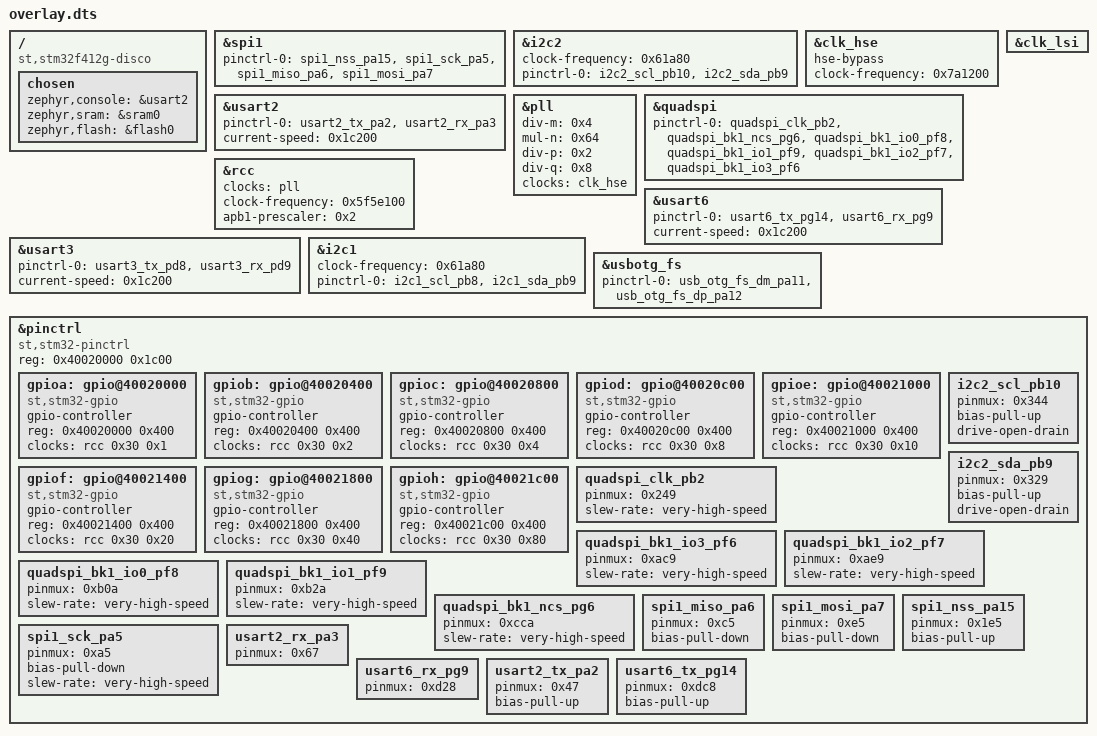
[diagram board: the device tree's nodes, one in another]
/ {
	compatible = "st,stm32f412g-disco";
	chosen {
		zephyr,console = &usart2;
		zephyr,sram = &sram0;
		zephyr,flash = &flash0;
	};
};
&spi1{
	status = "okay";
	pinctrl-0 = < &spi1_nss_pa15 &spi1_sck_pa5 &spi1_miso_pa6 &spi1_mosi_pa7 >;
	pinctrl-names = "default";
};
&i2c2{
	clock-frequency = < 0x61a80 >;
	status = "okay";
	pinctrl-0 = < &i2c2_scl_pb10 &i2c2_sda_pb9 >;
	pinctrl-names = "default";
};
&clk_hse{
	status = "okay";
	hse-bypass;
	clock-frequency = < 0x7a1200 >;
};
&clk_lsi{
	status = "okay";
};
&usart2{
	status = "okay";
	pinctrl-0 = < &usart2_tx_pa2 &usart2_rx_pa3 >;
	pinctrl-names = "default";
	current-speed = < 0x1c200 >;
};
&pll{
	status = "okay";
	div-m = < 0x4 >;
	mul-n = < 0x64 >;
	div-p = < 0x2 >;
	div-q = < 0x8 >;
	clocks = < &clk_hse >;
};
&quadspi{
	status = "okay";
	pinctrl-0 = < &quadspi_clk_pb2 &quadspi_bk1_ncs_pg6 &quadspi_bk1_io0_pf8 &quadspi_bk1_io1_pf9 &quadspi_bk1_io2_pf7 &quadspi_bk1_io3_pf6 >;
	pinctrl-names = "default";
};
&rcc{
	clocks = < &pll >;
	clock-frequency = < 0x5f5e100 >;
	apb1-prescaler = < 0x2 >;
};
&usart6{
	status = "okay";
	pinctrl-0 = < &usart6_tx_pg14 &usart6_rx_pg9 >;
	pinctrl-names = "default";
	current-speed = < 0x1c200 >;
};
&usart3{
	status = "okay";
	pinctrl-0 = < &usart3_tx_pd8 &usart3_rx_pd9 >;
	pinctrl-names = "default";
	current-speed = < 0x1c200 >;
};
&i2c1{
	clock-frequency = < 0x61a80 >;
	status = "okay";
	pinctrl-0 = < &i2c1_scl_pb8 &i2c1_sda_pb9 >;
	pinctrl-names = "default";
};
&usbotg_fs{
	status = "okay";
	pinctrl-0 = < &usb_otg_fs_dm_pa11 &usb_otg_fs_dp_pa12 >;
	pinctrl-names = "default";
};
&pinctrl{
	compatible = "st,stm32-pinctrl";
	#address-cells = < 0x1 >;
	#size-cells = < 0x1 >;
	reg = < 0x40020000 0x1c00 >;
	gpioa: gpio@40020000 {
		compatible = "st,stm32-gpio";
		gpio-controller;
		#gpio-cells = < 0x2 >;
		reg = < 0x40020000 0x400 >;
		clocks = < &rcc 0x30 0x1 >;
	};
	gpiob: gpio@40020400 {
		compatible = "st,stm32-gpio";
		gpio-controller;
		#gpio-cells = < 0x2 >;
		reg = < 0x40020400 0x400 >;
		clocks = < &rcc 0x30 0x2 >;
	};
	gpioc: gpio@40020800 {
		compatible = "st,stm32-gpio";
		gpio-controller;
		#gpio-cells = < 0x2 >;
		reg = < 0x40020800 0x400 >;
		clocks = < &rcc 0x30 0x4 >;
	};
	gpiod: gpio@40020c00 {
		compatible = "st,stm32-gpio";
		gpio-controller;
		#gpio-cells = < 0x2 >;
		reg = < 0x40020c00 0x400 >;
		clocks = < &rcc 0x30 0x8 >;
	};
	gpioe: gpio@40021000 {
		compatible = "st,stm32-gpio";
		gpio-controller;
		#gpio-cells = < 0x2 >;
		reg = < 0x40021000 0x400 >;
		clocks = < &rcc 0x30 0x10 >;
	};
	gpiof: gpio@40021400 {
		compatible = "st,stm32-gpio";
		gpio-controller;
		#gpio-cells = < 0x2 >;
		reg = < 0x40021400 0x400 >;
		clocks = < &rcc 0x30 0x20 >;
	};
	gpiog: gpio@40021800 {
		compatible = "st,stm32-gpio";
		gpio-controller;
		#gpio-cells = < 0x2 >;
		reg = < 0x40021800 0x400 >;
		clocks = < &rcc 0x30 0x40 >;
	};
	gpioh: gpio@40021c00 {
		compatible = "st,stm32-gpio";
		gpio-controller;
		#gpio-cells = < 0x2 >;
		reg = < 0x40021c00 0x400 >;
		clocks = < &rcc 0x30 0x80 >;
	};
	i2c2_scl_pb10: i2c2_scl_pb10 {
		pinmux = < 0x344 >;
		bias-pull-up;
		drive-open-drain;
	};
	i2c2_sda_pb9: i2c2_sda_pb9 {
		pinmux = < 0x329 >;
		bias-pull-up;
		drive-open-drain;
	};
	quadspi_clk_pb2: quadspi_clk_pb2 {
		pinmux = < 0x249 >;
		slew-rate = "very-high-speed";
	};
	quadspi_bk1_io3_pf6: quadspi_bk1_io3_pf6 {
		pinmux = < 0xac9 >;
		slew-rate = "very-high-speed";
	};
	quadspi_bk1_io2_pf7: quadspi_bk1_io2_pf7 {
		pinmux = < 0xae9 >;
		slew-rate = "very-high-speed";
	};
	quadspi_bk1_io0_pf8: quadspi_bk1_io0_pf8 {
		pinmux = < 0xb0a >;
		slew-rate = "very-high-speed";
	};
	quadspi_bk1_io1_pf9: quadspi_bk1_io1_pf9 {
		pinmux = < 0xb2a >;
		slew-rate = "very-high-speed";
	};
	quadspi_bk1_ncs_pg6: quadspi_bk1_ncs_pg6 {
		pinmux = < 0xcca >;
		slew-rate = "very-high-speed";
	};
	spi1_miso_pa6: spi1_miso_pa6 {
		pinmux = < 0xc5 >;
		bias-pull-down;
	};
	spi1_mosi_pa7: spi1_mosi_pa7 {
		pinmux = < 0xe5 >;
		bias-pull-down;
	};
	spi1_nss_pa15: spi1_nss_pa15 {
		pinmux = < 0x1e5 >;
		bias-pull-up;
	};
	spi1_sck_pa5: spi1_sck_pa5 {
		pinmux = < 0xa5 >;
		bias-pull-down;
		slew-rate = "very-high-speed";
	};
	usart2_rx_pa3: usart2_rx_pa3 {
		pinmux = < 0x67 >;
	};
	usart6_rx_pg9: usart6_rx_pg9 {
		pinmux = < 0xd28 >;
	};
	usart2_tx_pa2: usart2_tx_pa2 {
		pinmux = < 0x47 >;
		bias-pull-up;
	};
	usart6_tx_pg14: usart6_tx_pg14 {
		pinmux = < 0xdc8 >;
		bias-pull-up;
	};
};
